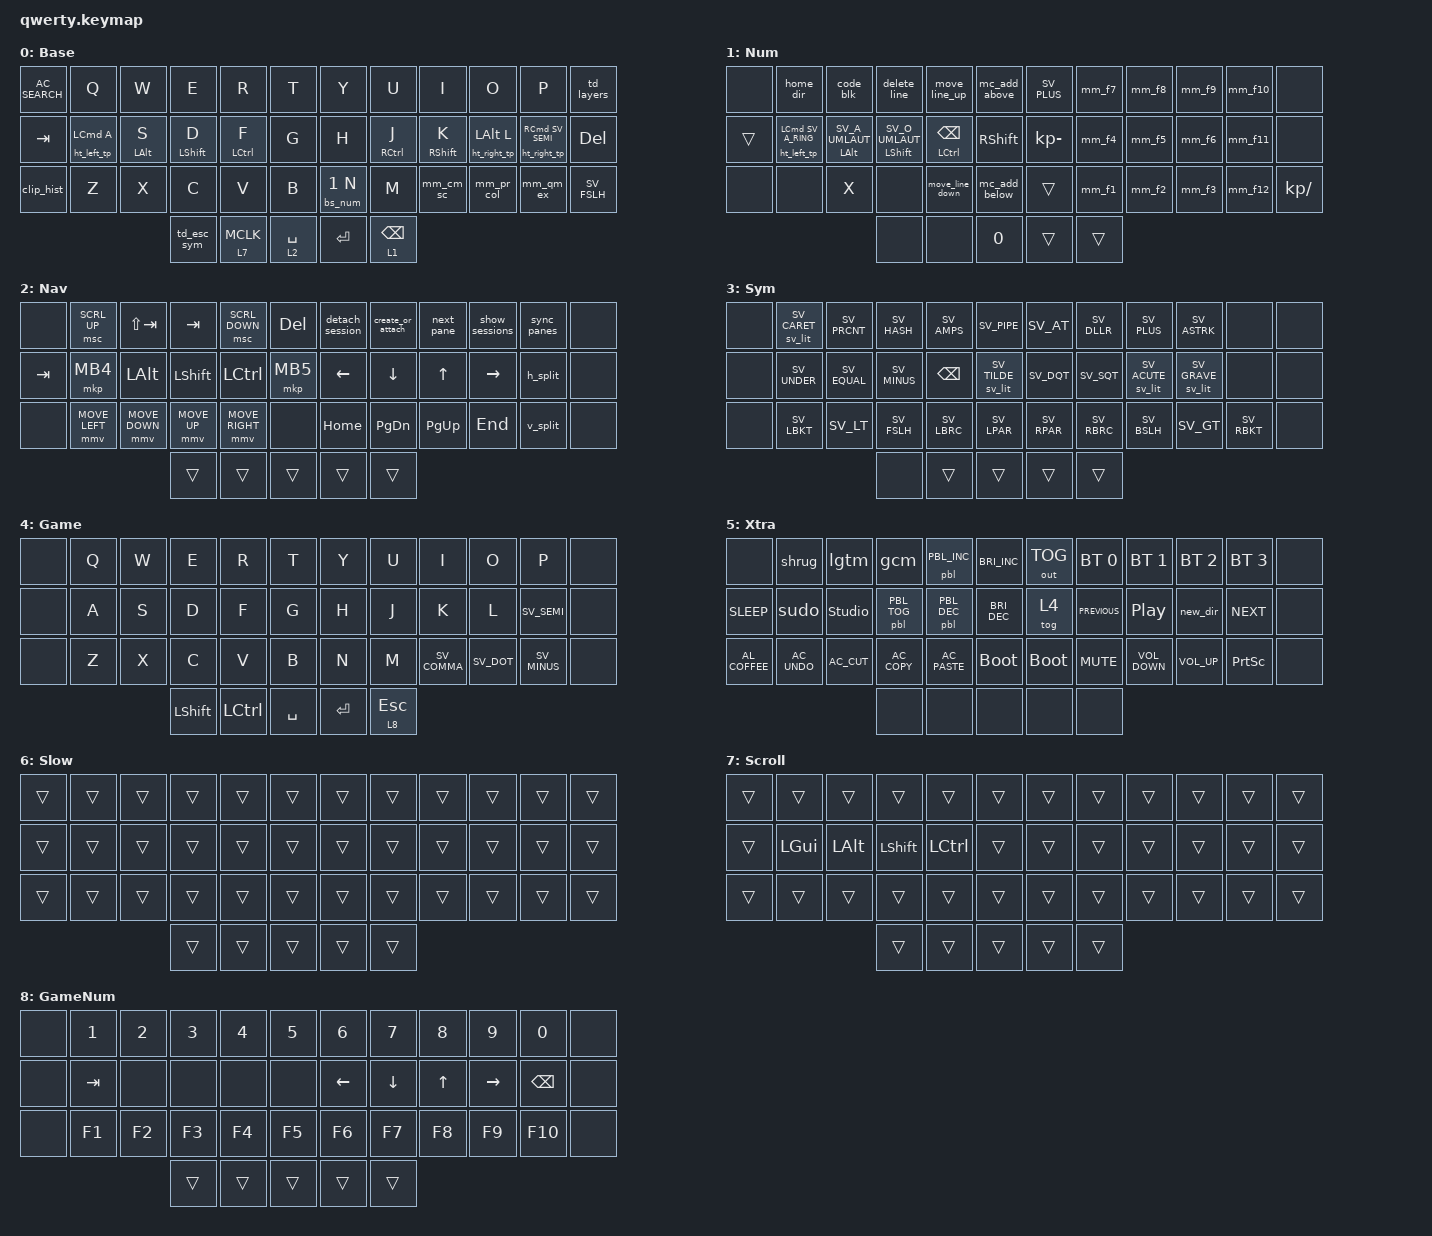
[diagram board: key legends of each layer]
/* upstream bindings and behaviors */
#include <behaviors.dtsi>
#include <dt-bindings/zmk/bt.h>
#include <dt-bindings/zmk/keys.h>
#include <dt-bindings/zmk/mouse.h>
#include <dt-bindings/zmk/outputs.h>
#include <behaviors/mouse_keys.dtsi>
#include <dt-bindings/zmk/ext_power.h>

/* OS layout Swedish: shared macros/behaviors emit SV_* keycodes */
#define LOCALE_SV

/* local overlays */
#include "keymap_features/prospector_brightness.dtsi"
#include "keymap_features/macros.dtsi"
#include "keymap_features/behaviors.dtsi"
#include "keymap_features/combos.dtsi"

/ {
/* --- KEYMAP CONFIG --- */
// ╭──────┬──────┬──────┬──────┬──────┬──────╮  ╭──────┬──────┬──────┬──────┬──────┬──────╮
//    00     01     02     03    04      05        06     07     08     09     10     11
// ├──────┼──────┼──────┼──────┼──────┼──────┤  ├──────┼──────┼──────┼──────┼──────┼──────┤
//    12     13     14     15    16      17        18     19     20     21     22     23
// ├──────┼──────┼──────┼──────┼──────┼──────┤  ├──────┼──────┼──────┼──────┼──────┼──────┤
//    24     25     26     27    28      29        30     31     32     33     34     35
// ╰──────┴──────┴──────┼──────┼──────┼──────┤  ├──────┼──────┼──────┴──────┴──────┴──────╯
//                         36     37     38        39     40
//                      ╰──────┴──────┴──────╯  ╰──────┴──────╯
// #define BASE    0
// #define NUM     1
// #define NAV     2
// #define SYM     3
// #define GAME    4
// #define EXTRAS  5
// #define SLOW    6
// #define SCROLL  7

// This shared keymap builds for prospector and non-prospector firmwares. 
// This stubs the key bindings that are contained in the prospector module
// so non-prospector firmware can build.
#ifndef CONFIG_SHIELD_PROSPECTOR_ADAPTER
    behaviors {
        /omit-if-no-ref/ pbl: prospector_brightness_stub {
            compatible = "zmk,behavior-macro-two-param";
            #binding-cells = <2>;
            bindings = <&none>;
        };
    };
#endif

    behaviors {
        // Hold = layer as soon as another key is pressed; tap = keycode
        hp_lt: hold_preferred_layer_tap {
            compatible = "zmk,behavior-hold-tap";
            #binding-cells = <2>;
            flavor = "hold-preferred";
            tapping-term-ms = <200>;
            bindings = <&mo>, <&kp>;
        };

        // 1x: Esc / hold SYM, 2x hold: SCROLL, 3x hold: SLOW
        td_esc_sym: td_esc_sym {
            compatible = "zmk,behavior-tap-dance";
            #binding-cells = <0>;
            tapping-term-ms = <150>;
            bindings = <&hp_lt 3 ESC>, <&mo 7>, <&mo 6>;
        };

        // Tap = mouse button, hold = layer (Click thumb: middle click / SCROLL)
        mkp_lt: mouse_button_layer_tap {
            compatible = "zmk,behavior-hold-tap";
            #binding-cells = <2>;
            flavor = "hold-preferred";
            tapping-term-ms = <150>;
            bindings = <&mo>, <&mkp>;
        };

        // Backspace thumb / hold NUM. No prior-idle, so it works right after a
        // mod (e.g. Gui then NUM then digit); balanced = NUM once a key is tapped.
        bs_num_thumb: bs_num_thumb {
            compatible = "zmk,behavior-hold-tap";
            #binding-cells = <2>;
            flavor = "balanced";
            tapping-term-ms = <200>;
            quick-tap-ms = <175>;
            bindings = <&mo>, <&kp>;
        };

        // Space / hold NAV. Fast typing always taps (prior idle); NAV once
        // another key is tapped while held; tap-then-hold repeats space.
        space_nav: space_nav {
            compatible = "zmk,behavior-hold-tap";
            #binding-cells = <2>;
            flavor = "balanced";
            tapping-term-ms = <200>;
            quick-tap-ms = <175>;
            require-prior-idle-ms = <150>;
            bindings = <&mo>, <&kp>;
        };
    };

    // Left thumb clicks: Esc+Click = left, Click+Space = right (Click alone = middle)
    combos {
        compatible = "zmk,combos";
        combo_thumb_left_click {
            bindings = <&mkp LCLK>;
            key-positions = <36 37>;
            layers = <0 1 2 3 5 6 7>;
        };
        combo_thumb_right_click {
            bindings = <&mkp RCLK>;
            key-positions = <37 38>;
            layers = <0 1 2 3 5 6 7>;
        };

        // Media, right hand only: vertical pairs (same finger can't roll them)
        combo_media_prev {
            bindings = <&kp C_PREV>;
            key-positions = <7 19>;
            layers = <0>;
        };
        combo_media_play {
            bindings = <&kp C_PLAY_PAUSE>;
            key-positions = <8 20>;
            layers = <0>;
        };
        combo_media_next {
            bindings = <&kp C_NEXT>;
            key-positions = <9 21>;
            layers = <0>;
        };
    };

    keymap {
        compatible = "zmk,keymap";
        BASE {
            display-name = "Base";
            bindings = <
// ╭───────────────┬────────────────┬────────────────┬─────────────────┬─────────────────┬──────╮  ╭──────┬──────────────────┬──────────────────┬─────────────────┬─────────────────┬─────────────╮
    &kp C_AC_SEARCH  &kp Q            &kp W            &kp E             &kp R             &kp T    &kp Y   &kp U              &kp I              &kp O             &kp P           &td_layers
// ├───────────────┼────────────────┼────────────────┼─────────────────┼─────────────────┼──────┤  ├──────┼──────────────────┼──────────────────┼─────────────────┼─────────────────┼─────────────┤
    &kp TAB          &ht_left_tp LCMD A  &ht_left LALT S  &ht_left LSHFT D  &ht_left LCTRL F  &kp G    &kp H   &ht_right RCTRL J  &ht_right RSHFT K  &ht_right_tp LALT L  &ht_right_tp RCMD SV_SEMI   &kp DEL
// ├───────────────┼────────────────┼────────────────┼─────────────────┼─────────────────┼──────┤  ├──────┼──────────────────┼──────────────────┼─────────────────┼─────────────────┼─────────────┤
    &clip_hist       &kp Z            &kp X            &kp C             &kp V             &kp B    &bs_num 1 N   &kp M              &mm_cm_sc          &mm_pr_col        &mm_qm_ex          &kp SV_FSLH
// ╰───────────────┴────────────────┴────────────────┼─────────────────┼─────────────────┼──────┤  ├──────┼──────────────────┼──────────────────┴─────────────────┴─────────────────┴─────────────╯
                                                             &td_esc_sym         &mkp_lt 7 MCLK  &space_nav 2 SPACE   &kp ENTER  &bs_num_thumb 1 BACKSPACE
                                                         // ╰──────────────────┴─────────┴──────╯  ╰──────────┴──────────────╯
            >;
        };

        NUM {
            display-name = "Num";
            bindings = <
&none    &home_dir       &code_blk       &delete_line    &move_line_up    &mc_add_above    &kp SV_PLUS  &mm_f7  &mm_f8  &mm_f9  &mm_f10  &none
&trans   &ht_left_tp LCMD SV_A_RING  &ht_left LALT SV_A_UMLAUT  &ht_left LSHFT SV_O_UMLAUT  &ht_left LCTRL BACKSPACE  &kp RSHIFT       &kp KP_MINUS &mm_f4  &mm_f5  &mm_f6  &mm_f11  &none
&none    &none           &kp X           &none           &move_line_down  &mc_add_below    &trans       &mm_f1  &mm_f2  &mm_f3  &mm_f12  &kp KP_SLASH
                                         &none           &none            &kp N0           &trans       &trans
            >;
        };

        NAV {
            display-name = "Nav";
            bindings = <
&none    &msc SCRL_UP    &kp LS(TAB)     &kp TAB      &msc SCRL_DOWN  &kp DEL             &detach_session  &create_or_attach  &next_pane   &show_sessions  &sync_panes       &none
&kp TAB  &mkp MB4        &kp LALT        &kp LSHFT    &kp LCTRL       &mkp MB5            &kp LEFT_ARROW   &kp DOWN           &kp UP       &kp RIGHT_ARROW &h_split          &none
&none    &mmv MOVE_LEFT  &mmv MOVE_DOWN  &mmv MOVE_UP &mmv MOVE_RIGHT &none               &kp HOME         &kp PG_DN          &kp PG_UP    &kp END         &v_split          &none
                                                      &trans  &trans  &trans              &trans  &trans
            >;
        };

        // Kyria-style: openers on left bottom row, closers mirrored on right
        SYM {
            display-name = "Sym";
            bindings = <
&none  &sv_lit SV_CARET  &kp SV_PRCNT  &kp SV_HASH   &kp SV_AMPS    &kp SV_PIPE       &kp SV_AT    &kp SV_DLLR  &kp SV_PLUS       &kp SV_ASTRK      &none        &none
&none  &kp SV_UNDER      &kp SV_EQUAL  &kp SV_MINUS  &kp BACKSPACE  &sv_lit SV_TILDE  &kp SV_DQT   &kp SV_SQT   &sv_lit SV_ACUTE  &sv_lit SV_GRAVE  &none        &none
&none  &kp SV_LBKT       &kp SV_LT     &kp SV_FSLH   &kp SV_LBRC    &kp SV_LPAR       &kp SV_RPAR  &kp SV_RBRC  &kp SV_BSLH       &kp SV_GT         &kp SV_RBKT  &none
                                   &none         &trans         &trans           &trans        &trans
            >;
        };

        // Plain QWERTY, no hold-taps so keys can be held. Toggle from XTRA (H).
        // Right outer thumb: tap Esc, hold GAME_NUM (must sit above GAME to show through).
        GAME {
            display-name = "Game";
            bindings = <
&none  &kp Q  &kp W  &kp E  &kp R  &kp T    &kp Y  &kp U  &kp I      &kp O      &kp P        &none
&none  &kp A  &kp S  &kp D  &kp F  &kp G    &kp H  &kp J  &kp K      &kp L      &kp SV_SEMI  &none
&none  &kp Z  &kp X  &kp C  &kp V  &kp B    &kp N  &kp M  &kp SV_COMMA  &kp SV_DOT  &kp SV_MINUS  &none
                     &kp LSHIFT  &kp LCTRL  &kp SPACE    &kp ENTER  &hp_lt 8 ESC
            >;
        };

        // B / N: bootloader for left / right half (runs on the half pressed)
        EXTRAS {
            display-name = "Xtra";
            bindings = <
&none             &shrug          &lgtm           &gcm            &pbl PBL_INC    &kp C_BRIGHTNESS_INC    &out OUT_TOG  &bt BT_SEL 0    &bt BT_SEL 1       &bt BT_SEL 2      &bt BT_SEL 3     &none
&kp C_SLEEP       &sudo           &studio_unlock  &pbl PBL_TOG    &pbl PBL_DEC    &kp C_BRIGHTNESS_DEC    &tog 4        &kp C_PREVIOUS  &kp C_PLAY_PAUSE   &new_dir          &kp C_NEXT       &none
&kp C_AL_COFFEE   &kp C_AC_UNDO   &kp C_AC_CUT    &kp C_AC_COPY   &kp C_AC_PASTE  &bootloader             &bootloader   &kp K_MUTE      &kp C_VOLUME_DOWN  &kp C_VOLUME_UP   &kp PRINTSCREEN  &none
                                                                                   &none  &none  &none    &none         &none
            >;
        };

        SLOW {
            display-name = "Slow";
            bindings = <
// ╭────────┬────────┬────────┬────────┬────────┬────────╮  ╭────────┬────────┬────────┬────────┬────────┬────────╮
    &trans    &trans   &trans   &trans   &trans   &trans      &trans   &trans   &trans   &trans   &trans   &trans
// ├────────┼────────┼────────┼────────┼────────┼────────┤  ├────────┼────────┼────────┼────────┼────────┼────────┤
    &trans    &trans   &trans   &trans   &trans   &trans      &trans   &trans   &trans   &trans   &trans   &trans
// ├────────┼────────┼────────┼────────┼────────┼────────┤  ├────────┼────────┼────────┼────────┼────────┼────────┤
    &trans    &trans   &trans   &trans   &trans   &trans      &trans   &trans   &trans   &trans   &trans   &trans
// ╰────────┴────────┴────────┼────────┼────────┼────────┤  ├────────┼────────┼────────┴────────┴────────┴────────╯
                                  &trans   &trans   &trans      &trans   &trans
                             // ╰────────┴────────┴────────╯  ╰────────┴────────╯
            >;
        };

        // Trackball scrolls; left home row = instant mods (Ctrl+scroll zoom etc.)
        SCROLL {
            display-name = "Scroll";
            bindings = <
&trans  &trans     &trans    &trans     &trans     &trans    &trans  &trans  &trans  &trans  &trans  &trans
&trans  &kp LGUI   &kp LALT  &kp LSHFT  &kp LCTRL  &trans    &trans  &trans  &trans  &trans  &trans  &trans
&trans  &trans     &trans    &trans     &trans     &trans    &trans  &trans  &trans  &trans  &trans  &trans
                             &trans     &trans     &trans    &trans  &trans
            >;
        };

        // Numbers/F-keys/arrows while in GAME (hold right outer thumb)
        GAME_NUM {
            display-name = "GameNum";
            bindings = <
&none  &kp N1   &kp N2  &kp N3  &kp N4  &kp N5     &kp N6   &kp N7    &kp N8  &kp N9     &kp N0     &none
&none  &kp TAB  &none   &none   &none   &none      &kp LEFT &kp DOWN  &kp UP  &kp RIGHT  &kp BSPC   &none
&none  &kp F1   &kp F2  &kp F3  &kp F4  &kp F5     &kp F6   &kp F7    &kp F8  &kp F9     &kp F10    &none
                        &trans  &trans  &trans     &trans   &trans
            >;
        };
    };
};

/* NUM F-keys only via NUM's own Shift (G, RShift); home-row Shift + digit
   stays Shift+digit so Gui+Shift+N (move to workspace) works. */
&mm_f1 { mods = <MOD_RSFT>; };
&mm_f2 { mods = <MOD_RSFT>; };
&mm_f3 { mods = <MOD_RSFT>; };
&mm_f4 { mods = <MOD_RSFT>; };
&mm_f5 { mods = <MOD_RSFT>; };
&mm_f6 { mods = <MOD_RSFT>; };
&mm_f7 { mods = <MOD_RSFT>; };
&mm_f8 { mods = <MOD_RSFT>; };
&mm_f9 { mods = <MOD_RSFT>; };
&mm_f10 { mods = <MOD_RSFT>; };
&mm_f11 { mods = <MOD_RSFT>; };
&mm_f12 { mods = <MOD_RSFT>; };
